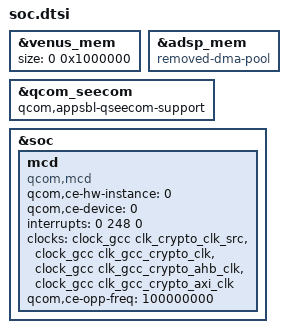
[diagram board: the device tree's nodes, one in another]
&venus_mem {
	size = <0 0x1000000>;
};

&adsp_mem {
	compatible = "removed-dma-pool";
};

&qcom_seecom {
	qcom,appsbl-qseecom-support;
};

&soc {
	mcd {
		compatible = "qcom,mcd";
		qcom,ce-hw-instance = <0>;
		qcom,ce-device = <0>;
		interrupts = <0 248 0>;
		interrupt-names = "mcd_irq";
		clocks = <&clock_gcc clk_crypto_clk_src>,
			 <&clock_gcc clk_gcc_crypto_clk>,
			 <&clock_gcc clk_gcc_crypto_ahb_clk>,
			 <&clock_gcc clk_gcc_crypto_axi_clk>;
		clock-names = "core_clk_src", "core_clk",
				"iface_clk", "bus_clk";
		qcom,ce-opp-freq = <100000000>;
	};
};
